AUTOSAR XML (schema 314)
package /ComponentType
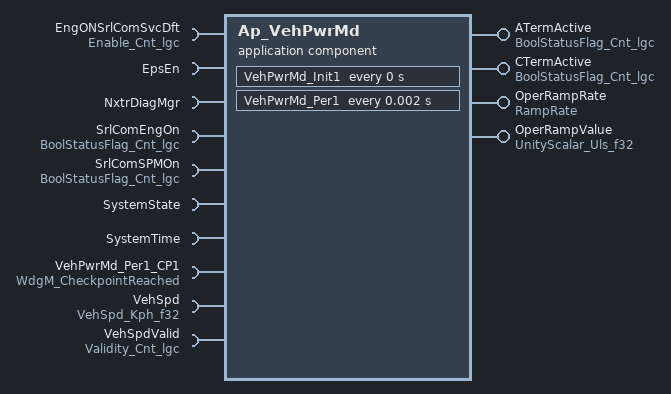
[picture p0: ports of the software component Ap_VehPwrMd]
  application software component type Ap_VehPwrMd
    4 x provide port:
      ATermActive: unqueued-sender-com-spec{data-element=Cnt_lgc, can-invalidate=false, init-value=D_TRUE_CNT_LGC}, provided-interface=BoolStatusFlag_Cnt_lgc
      CTermActive: unqueued-sender-com-spec{data-element=Cnt_lgc, can-invalidate=false, init-value=D_FALSE_CNT_LGC}, provided-interface=BoolStatusFlag_Cnt_lgc
      OperRampRate: unqueued-sender-com-spec{data-element=XpmS_f32, can-invalidate=false, init-value=D_ZERO_ULS_F32}, provided-interface=RampRate
      OperRampValue: unqueued-sender-com-spec{data-element=Uls_f32, can-invalidate=false, init-value=D_ZERO_ULS_F32}, provided-interface=UnityScalar_Uls_f32
    10 x require port:
      EngONSrlComSvcDft: unqueued-receiver-com-spec{data-element=Cnt_lgc, init-value=D_FALSE_CNT_LGC}, required-interface=Enable_Cnt_lgc
      EpsEn: client-com-spec=OP_GET, required-interface=EpsEn
      NxtrDiagMgr: required-com-specs=[GetNTCActive, GetNTCFailed, GetNTCStatus, SetNTCStatus], required-interface=NxtrDiagMgr
      SrlComEngOn: unqueued-receiver-com-spec{data-element=Cnt_lgc, init-value=D_FALSE_CNT_LGC}, required-interface=BoolStatusFlag_Cnt_lgc
      SrlComSPMOn: unqueued-receiver-com-spec{data-element=Cnt_lgc, init-value=D_FALSE_CNT_LGC}, required-interface=BoolStatusFlag_Cnt_lgc
      SystemState: required-interface=SystemState
      SystemTime: required-interface=SystemTime
        required-com-specs:
          DtrmnElapsedTime_mS_u16
          DtrmnElapsedTime_mS_u32
          DtrmnElapsedTime_uS_u16
          DtrmnElapsedTime_uS_u32
          GetSystemTime_mS_u32
          GetSystemTime_uS_u32
      VehPwrMd_Per1_CP1: client-com-spec=CheckpointReached, required-interface=WdgM_CheckpointReached
      VehSpd: unqueued-receiver-com-spec{data-element=Kph_f32, init-value=D_ZERO_ULS_F32}, required-interface=VehSpd_Kph_f32
      VehSpdValid: unqueued-receiver-com-spec{data-element=Cnt_lgc, init-value=D_FALSE_CNT_LGC}, required-interface=Validity_Cnt_lgc
  internal behavior Ap_VehPwrMd_InternalBehavior: component=Ap_VehPwrMd
    timing event VehPwrMd_Init1_InitEvent: start-on-event=VehPwrMd_Init1, period=0
    timing event TMT_VehPwrMd_Per1: start-on-event=VehPwrMd_Per1, period=0.002
    mode switch event MST_VehPwrMd_Trns1_0: start-on-event=VehPwrMd_Trns1, activation=ENTRY, mode=SystemState.Mode.OFF
    mode switch event MST_VehPwrMd_Trns2_0: start-on-event=VehPwrMd_Trns2, activation=EXIT, mode=SystemState.Mode.OFF
    port-api-options:
      enable-take-address=false, indirect-api=false, port=ATermActive
      enable-take-address=false, indirect-api=false, port=CTermActive
      enable-take-address=false, indirect-api=false, port=EngONSrlComSvcDft
      enable-take-address=false, indirect-api=false, port=EpsEn
      enable-take-address=false, indirect-api=false, port=NxtrDiagMgr
      enable-take-address=false, indirect-api=false, port=OperRampRate
      enable-take-address=false, indirect-api=false, port=OperRampValue
      enable-take-address=false, indirect-api=false, port=SrlComEngOn
      enable-take-address=false, indirect-api=false, port=SrlComSPMOn
      enable-take-address=false, indirect-api=false, port=SystemState
      enable-take-address=false, indirect-api=false, port=SystemTime
      enable-take-address=false, indirect-api=false, port=VehPwrMd_Per1_CP1
      enable-take-address=false, indirect-api=false, port=VehSpd
      enable-take-address=false, indirect-api=false, port=VehSpdValid
    4 x runnable:
      VehPwrMd_Init1
        data write access WRITE_OperRampRate_XpmS_f32: data-element=OperRampRate.XpmS_f32
        data write access WRITE_OperRampValue_Uls_f32: data-element=OperRampValue.Uls_f32
      VehPwrMd_Per1
        5 x data read access:
          READ_EngONSrlComSvcDft_Cnt_lgc: data-element=EngONSrlComSvcDft.Cnt_lgc
          READ_SrlComEngOn_Cnt_lgc: data-element=SrlComEngOn.Cnt_lgc
          READ_SrlComSPMOn_Cnt_lgc: data-element=SrlComSPMOn.Cnt_lgc
          READ_VehSpd_Kph_f32: data-element=VehSpd.Kph_f32
          READ_VehSpdValid_Cnt_lgc: data-element=VehSpdValid.Cnt_lgc
        4 x data write access:
          WRITE_ATermActive_Cnt_lgc: data-element=ATermActive.Cnt_lgc
          WRITE_CTermActive_Cnt_lgc: data-element=CTermActive.Cnt_lgc
          WRITE_OperRampRate_XpmS_f32: data-element=OperRampRate.XpmS_f32
          WRITE_OperRampValue_Uls_f32: data-element=OperRampValue.Uls_f32
        6 x sync call, all with timeout=0:
          SC_EpsEn_OP_GET: operation=EpsEn.OP_GET
          SC_NxtrDiagMgr_GetNTCFailed: operation=NxtrDiagMgr.GetNTCFailed
          SC_NxtrDiagMgr_SetNTCStatus: operation=NxtrDiagMgr.SetNTCStatus
          SC_SystemTime_DtrmnElapsedTime_mS_u16: operation=SystemTime.DtrmnElapsedTime_mS_u16
          SC_SystemTime_GetSystemTime_mS_u32: operation=SystemTime.GetSystemTime_mS_u32
          SC_VehPwrMd_Per1_CP1_CheckpointReached: operation=VehPwrMd_Per1_CP1.CheckpointReached
      VehPwrMd_Trns1
      VehPwrMd_Trns2
  swc implementation Ap_VehPwrMd_Implementation: behavior=Ap_VehPwrMd_InternalBehavior
    code-descriptors:
      code Code: type=SRC
